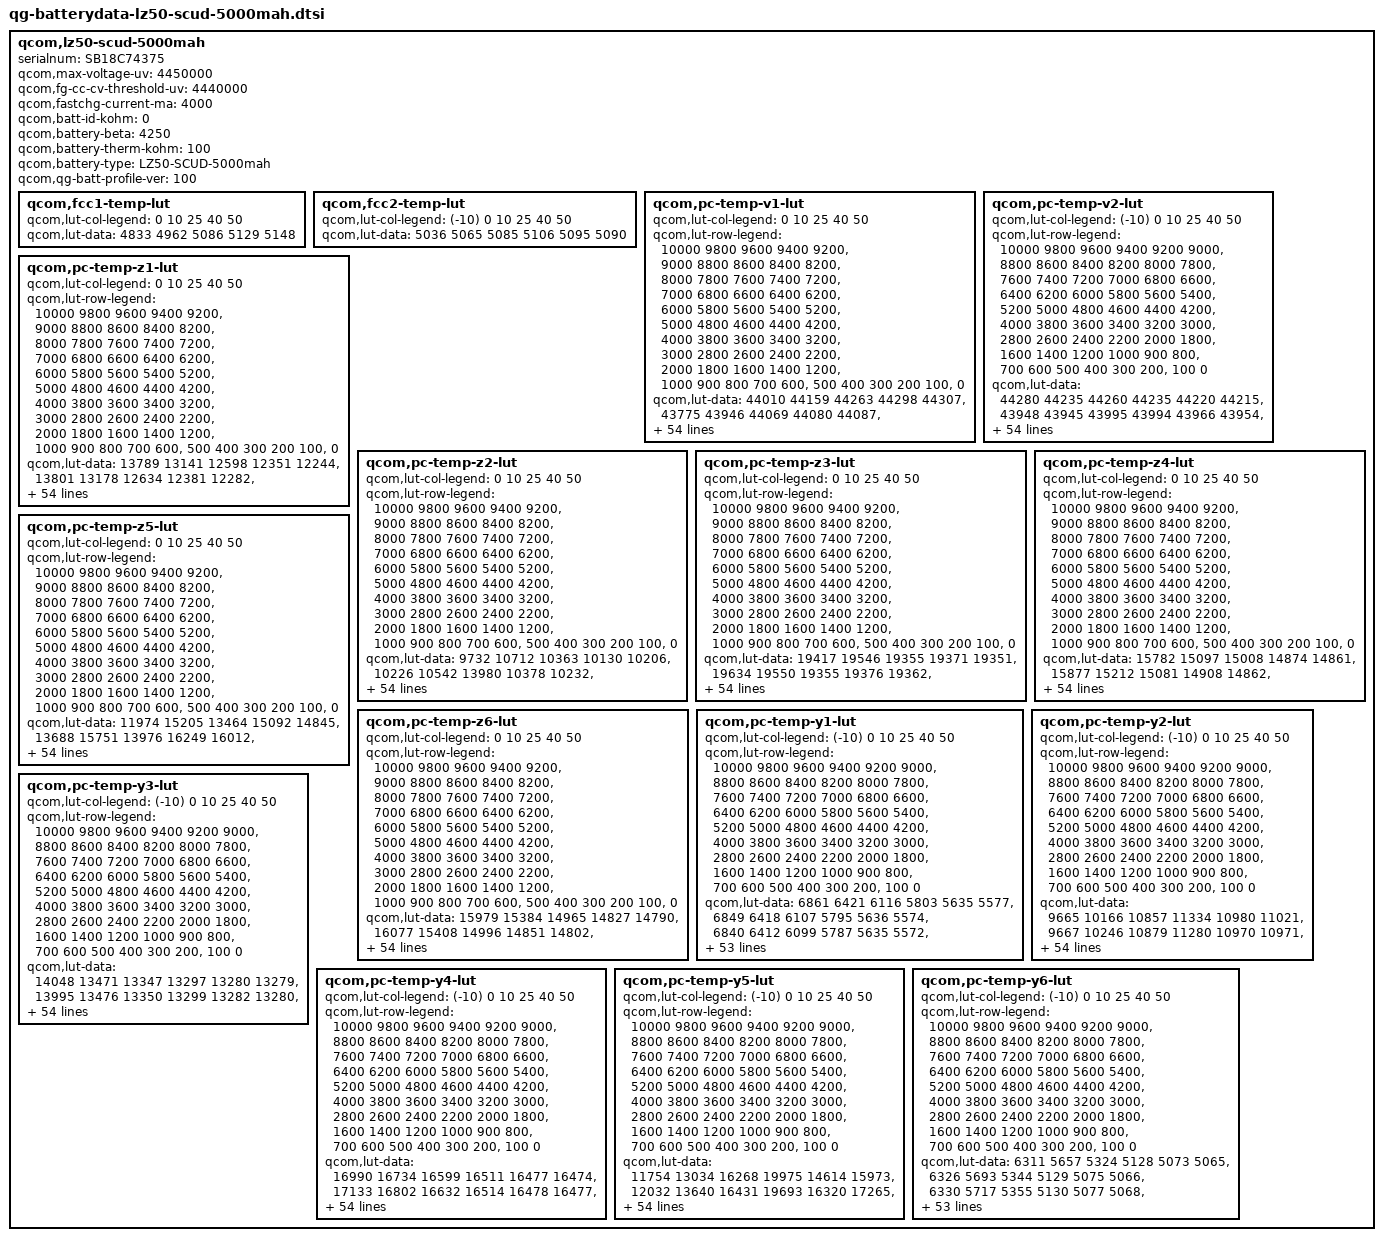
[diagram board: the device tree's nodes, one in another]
qcom,lz50-scud-5000mah {
    /* 4534034_lenovo_Nairobi_5000mAH_PM7250B_averaged_MasterSlave_Apr7th2020 */
    serialnum = "SB18C74375";
    qcom,max-voltage-uv = <4450000>;
    qcom,fg-cc-cv-threshold-uv = <4440000>;
    qcom,fastchg-current-ma = <4000>;
    qcom,batt-id-kohm = <0>;
    qcom,battery-beta = <4250>;
    qcom,battery-therm-kohm = <100>;
    qcom,battery-type = "LZ50-SCUD-5000mah";
    qcom,qg-batt-profile-ver = <100>;

	qcom,fcc1-temp-lut {
		qcom,lut-col-legend = <0 10 25 40 50>;
		qcom,lut-data = <4833 4962 5086 5129 5148>;
	};

	qcom,fcc2-temp-lut {
		qcom,lut-col-legend = <(-10) 0 10 25 40 50>;
		qcom,lut-data = <5036 5065 5085 5106 5095 5090>;
	};

	qcom,pc-temp-v1-lut {
		qcom,lut-col-legend = <0 10 25 40 50>;
		qcom,lut-row-legend = <10000 9800 9600 9400 9200>,
			<9000 8800 8600 8400 8200>,
			<8000 7800 7600 7400 7200>,
			<7000 6800 6600 6400 6200>,
			<6000 5800 5600 5400 5200>,
			<5000 4800 4600 4400 4200>,
			<4000 3800 3600 3400 3200>,
			<3000 2800 2600 2400 2200>,
			<2000 1800 1600 1400 1200>,
			<1000 900 800 700 600>,
			<500 400 300 200 100>,
			<0>;
		qcom,lut-data = <44010 44159 44263 44298 44307>,
			<43775 43946 44069 44080 44087>,
			<43539 43727 43872 43880 43887>,
			<43300 43501 43660 43678 43686>,
			<43059 43270 43435 43466 43477>,
			<42814 43032 43194 43239 43255>,
			<42572 42787 42950 43005 43023>,
			<42332 42542 42705 42766 42785>,
			<42096 42299 42459 42522 42539>,
			<41865 42057 42214 42278 42294>,
			<41639 41822 41972 42034 42051>,
			<41419 41590 41733 41793 41811>,
			<41203 41364 41499 41556 41573>,
			<40993 41149 41271 41322 41338>,
			<40779 40941 41050 41096 41111>,
			<40558 40732 40837 40876 40889>,
			<40343 40518 40627 40664 40675>,
			<40153 40312 40421 40460 40471>,
			<39981 40128 40223 40264 40276>,
			<39817 39957 40049 40082 40091>,
			<39659 39782 39879 39912 39922>,
			<39506 39605 39656 39709 39727>,
			<39357 39419 39349 39414 39443>,
			<39211 39196 39098 39140 39164>,
			<39066 38943 38952 38990 39008>,
			<38919 38767 38840 38882 38902>,
			<38774 38668 38741 38778 38796>,
			<38654 38594 38653 38674 38684>,
			<38557 38526 38571 38576 38575>,
			<38476 38466 38493 38484 38473>,
			<38419 38412 38421 38397 38378>,
			<38374 38360 38353 38318 38296>,
			<38334 38313 38290 38245 38226>,
			<38297 38268 38232 38177 38159>,
			<38262 38228 38181 38114 38090>,
			<38226 38188 38132 38055 38021>,
			<38191 38149 38082 37998 37955>,
			<38150 38107 38030 37944 37893>,
			<38087 38044 37964 37876 37817>,
			<38004 37950 37872 37776 37709>,
			<37905 37841 37763 37658 37584>,
			<37777 37717 37643 37540 37462>,
			<37631 37575 37506 37411 37333>,
			<37459 37408 37344 37254 37172>,
			<37339 37257 37195 37116 37041>,
			<37233 37161 37100 37027 36965>,
			<37193 37127 37069 36999 36935>,
			<37159 37111 37051 36977 36913>,
			<37123 37081 37028 36954 36887>,
			<37061 37022 36960 36879 36798>,
			<36834 36770 36692 36589 36478>,
			<36379 36312 36242 36134 36021>,
			<35785 35712 35651 35544 35427>,
			<34963 34881 34840 34738 34612>,
			<33626 33554 33574 33482 33333>,
			<30000 30000 30000 30000 30000>;
	};

	qcom,pc-temp-v2-lut {
		qcom,lut-col-legend = <(-10) 0 10 25 40 50>;
		qcom,lut-row-legend = <10000 9800 9600 9400 9200 9000>,
			<8800 8600 8400 8200 8000 7800>,
			<7600 7400 7200 7000 6800 6600>,
			<6400 6200 6000 5800 5600 5400>,
			<5200 5000 4800 4600 4400 4200>,
			<4000 3800 3600 3400 3200 3000>,
			<2800 2600 2400 2200 2000 1800>,
			<1600 1400 1200 1000 900 800>,
			<700 600 500 400 300 200>,
			<100 0>;
		qcom,lut-data = <44280 44235 44260 44235 44220 44215>,
			<43948 43945 43995 43994 43966 43954>,
			<43632 43672 43739 43759 43723 43706>,
			<43332 43418 43497 43531 43493 43475>,
			<43048 43184 43268 43312 43276 43259>,
			<42773 42946 43034 43085 43052 43038>,
			<42501 42694 42785 42845 42812 42800>,
			<42236 42437 42532 42599 42566 42556>,
			<41978 42183 42282 42353 42321 42311>,
			<41724 41929 42033 42106 42076 42065>,
			<41494 41677 41788 41862 41835 41822>,
			<41293 41414 41547 41621 41596 41584>,
			<41106 41168 41312 41385 41361 41350>,
			<40920 40986 41086 41153 41129 41120>,
			<40742 40846 40869 40926 40903 40895>,
			<40520 40661 40654 40706 40685 40677>,
			<40164 40356 40446 40493 40475 40467>,
			<39779 40027 40231 40286 40272 40263>,
			<39521 39777 39995 40094 40082 40076>,
			<39325 39562 39745 39906 39899 39895>,
			<39134 39349 39508 39692 39692 39692>,
			<38928 39132 39283 39435 39449 39455>,
			<38736 38924 39077 39194 39215 39223>,
			<38579 38728 38896 38994 39012 39019>,
			<38441 38543 38734 38817 38828 38832>,
			<38334 38392 38588 38669 38678 38679>,
			<38253 38265 38460 38542 38553 38552>,
			<38184 38163 38341 38430 38442 38440>,
			<38119 38090 38226 38328 38340 38336>,
			<38057 38031 38119 38233 38246 38242>,
			<37998 37975 38028 38145 38161 38157>,
			<37938 37923 37947 38062 38085 38081>,
			<37879 37872 37881 37985 38010 38005>,
			<37816 37819 37831 37916 37940 37930>,
			<37751 37766 37788 37849 37866 37851>,
			<37684 37709 37743 37779 37776 37753>,
			<37616 37646 37697 37709 37674 37636>,
			<37544 37577 37642 37634 37575 37526>,
			<37463 37498 37566 37555 37486 37432>,
			<37376 37410 37473 37472 37399 37341>,
			<37289 37312 37362 37383 37312 37254>,
			<37203 37203 37230 37285 37221 37165>,
			<37119 37093 37105 37158 37087 37030>,
			<37039 36984 36987 37025 36956 36898>,
			<36957 36878 36880 36915 36865 36811>,
			<36870 36758 36777 36862 36824 36774>,
			<36817 36699 36726 36845 36812 36762>,
			<36762 36644 36671 36821 36791 36741>,
			<36697 36590 36589 36775 36750 36695>,
			<36601 36499 36446 36661 36591 36524>,
			<36434 36319 36172 36327 36202 36132>,
			<36127 35903 35700 35800 35662 35594>,
			<35605 35271 35035 35109 34945 34881>,
			<34828 34330 34088 34137 33911 33873>,
			<33487 32806 32471 32663 32573 32513>,
			<31264 28190 27430 27573 28098 27439>;
	};

	qcom,pc-temp-z1-lut {
		qcom,lut-col-legend = <0 10 25 40 50>;
		qcom,lut-row-legend = <10000 9800 9600 9400 9200>,
			<9000 8800 8600 8400 8200>,
			<8000 7800 7600 7400 7200>,
			<7000 6800 6600 6400 6200>,
			<6000 5800 5600 5400 5200>,
			<5000 4800 4600 4400 4200>,
			<4000 3800 3600 3400 3200>,
			<3000 2800 2600 2400 2200>,
			<2000 1800 1600 1400 1200>,
			<1000 900 800 700 600>,
			<500 400 300 200 100>,
			<0>;
		qcom,lut-data = <13789 13141 12598 12351 12244>,
			<13801 13178 12634 12381 12282>,
			<13795 13197 12637 12383 12284>,
			<13789 13193 12638 12385 12283>,
			<13795 13183 12635 12384 12282>,
			<13817 13179 12627 12379 12280>,
			<13830 13183 12620 12372 12277>,
			<13814 13186 12615 12365 12274>,
			<13785 13182 12610 12358 12271>,
			<13776 13172 12602 12353 12269>,
			<13779 13162 12593 12349 12269>,
			<13782 13145 12589 12347 12270>,
			<13765 13130 12587 12348 12272>,
			<13723 13128 12586 12351 12275>,
			<13704 13130 12585 12351 12276>,
			<13706 13128 12583 12351 12276>,
			<13709 13111 12582 12350 12276>,
			<13708 13096 12583 12350 12276>,
			<13705 13099 12584 12349 12277>,
			<13700 13113 12585 12349 12277>,
			<13675 13120 12587 12351 12278>,
			<13640 13117 12588 12352 12279>,
			<13634 13114 12587 12352 12280>,
			<13653 13116 12587 12352 12280>,
			<13670 13120 12590 12353 12281>,
			<13676 13123 12596 12356 12282>,
			<13678 13129 12600 12358 12284>,
			<13679 13135 12604 12361 12287>,
			<13677 13136 12607 12365 12291>,
			<13675 13136 12611 12369 12295>,
			<13679 13137 12614 12373 12298>,
			<13688 13141 12617 12378 12303>,
			<13694 13145 12620 12385 12307>,
			<13693 13151 12623 12391 12312>,
			<13690 13159 12629 12396 12317>,
			<13690 13167 12635 12401 12323>,
			<13693 13175 12640 12406 12329>,
			<13698 13184 12644 12412 12333>,
			<13709 13194 12649 12418 12338>,
			<13729 13207 12658 12423 12342>,
			<13747 13216 12668 12428 12347>,
			<13781 13221 12675 12433 12352>,
			<13800 13226 12681 12439 12356>,
			<13802 13240 12688 12446 12360>,
			<13817 13262 12702 12454 12366>,
			<13844 13271 12708 12460 12370>,
			<13823 13263 12713 12459 12369>,
			<13825 13264 12707 12461 12371>,
			<13844 13255 12711 12466 12376>,
			<13840 13284 12712 12474 12383>,
			<13862 13273 12731 12481 12389>,
			<13863 13287 12738 12487 12399>,
			<13873 13313 12752 12506 12411>,
			<13891 13351 12778 12524 12431>,
			<13891 13351 12778 12524 12431>,
			<13891 13351 12778 12524 12431>;
	};

	qcom,pc-temp-z2-lut {
		qcom,lut-col-legend = <0 10 25 40 50>;
		qcom,lut-row-legend = <10000 9800 9600 9400 9200>,
			<9000 8800 8600 8400 8200>,
			<8000 7800 7600 7400 7200>,
			<7000 6800 6600 6400 6200>,
			<6000 5800 5600 5400 5200>,
			<5000 4800 4600 4400 4200>,
			<4000 3800 3600 3400 3200>,
			<3000 2800 2600 2400 2200>,
			<2000 1800 1600 1400 1200>,
			<1000 900 800 700 600>,
			<500 400 300 200 100>,
			<0>;
		qcom,lut-data = <9732 10712 10363 10130 10206>,
			<10226 10542 13980 10378 10232>,
			<10245 10432 13101 10446 10375>,
			<10250 10408 11720 10474 10406>,
			<10247 10393 11065 10479 10417>,
			<10242 10374 10636 10458 10413>,
			<10237 10344 10463 10425 10405>,
			<10231 10315 10422 10385 10391>,
			<10225 10290 10391 10337 10362>,
			<10223 10268 10365 10306 10330>,
			<10260 10254 10344 10282 10285>,
			<10296 10242 10326 10269 10254>,
			<10272 10236 10309 10265 10255>,
			<10202 10237 10299 10264 10261>,
			<10157 10240 10306 10268 10266>,
			<10136 10245 10325 10278 10278>,
			<10120 10257 10340 10292 10292>,
			<10135 10273 10355 10315 10303>,
			<10213 10289 10369 10339 10308>,
			<10266 10307 10383 10342 10286>,
			<10231 10322 10397 10335 10212>,
			<10170 10336 10435 10343 10175>,
			<10158 10348 10542 10494 10364>,
			<10171 10362 10606 10644 10595>,
			<10186 10377 10532 10543 10540>,
			<10200 10383 10419 10280 10301>,
			<10212 10376 10403 10206 10215>,
			<10222 10367 10418 10290 10374>,
			<10229 10365 10433 10379 10533>,
			<10235 10365 10446 10431 10588>,
			<10238 10366 10460 10486 10650>,
			<10239 10370 10475 10514 10613>,
			<10242 10375 10494 10513 10491>,
			<10247 10380 10504 10494 10371>,
			<10255 10386 10501 10448 10278>,
			<10262 10392 10498 10398 10203>,
			<10272 10399 10503 10391 10180>,
			<10282 10408 10514 10405 10186>,
			<10292 10420 10529 10425 10213>,
			<10304 10438 10564 10484 10320>,
			<10316 10448 10594 10543 10444>,
			<10328 10448 10599 10556 10488>,
			<10348 10449 10601 10561 10511>,
			<10394 10464 10597 10549 10535>,
			<9986 10574 10619 10490 10494>,
			<9784 10652 10650 10378 10301>,
			<9774 10634 10631 10377 10281>,
			<9851 10665 10609 10372 10280>,
			<9846 10728 10596 10395 10317>,
			<9799 10607 10638 10477 10377>,
			<9757 10717 10700 10413 10305>,
			<9700 10552 10631 10232 10108>,
			<9531 10372 10551 10172 10027>,
			<9405 10176 10451 10110 9984>,
			<9405 10176 10451 10110 9984>,
			<9405 10176 10451 10110 9984>;
	};

	qcom,pc-temp-z3-lut {
		qcom,lut-col-legend = <0 10 25 40 50>;
		qcom,lut-row-legend = <10000 9800 9600 9400 9200>,
			<9000 8800 8600 8400 8200>,
			<8000 7800 7600 7400 7200>,
			<7000 6800 6600 6400 6200>,
			<6000 5800 5600 5400 5200>,
			<5000 4800 4600 4400 4200>,
			<4000 3800 3600 3400 3200>,
			<3000 2800 2600 2400 2200>,
			<2000 1800 1600 1400 1200>,
			<1000 900 800 700 600>,
			<500 400 300 200 100>,
			<0>;
		qcom,lut-data = <19417 19546 19355 19371 19351>,
			<19634 19550 19355 19376 19362>,
			<19699 19556 19382 19397 19384>,
			<19739 19567 19418 19408 19397>,
			<19755 19580 19442 19417 19407>,
			<19764 19588 19461 19427 19415>,
			<19767 19593 19469 19433 19421>,
			<19762 19596 19470 19434 19427>,
			<19752 19596 19471 19434 19433>,
			<19750 19595 19470 19434 19435>,
			<19762 19593 19468 19433 19434>,
			<19774 19591 19466 19432 19432>,
			<19768 19588 19463 19430 19429>,
			<19748 19582 19460 19426 19425>,
			<19739 19574 19455 19422 19421>,
			<19750 19568 19449 19418 19417>,
			<19763 19564 19445 19414 19412>,
			<19769 19559 19442 19410 19407>,
			<19773 19554 19439 19406 19400>,
			<19774 19547 19435 19400 19393>,
			<19762 19545 19430 19392 19384>,
			<19743 19550 19432 19390 19379>,
			<19737 19557 19450 19400 19386>,
			<19736 19566 19461 19410 19393>,
			<19735 19577 19451 19400 19386>,
			<19738 19581 19434 19375 19361>,
			<19744 19577 19427 19368 19352>,
			<19746 19572 19423 19373 19376>,
			<19743 19567 19422 19379 19401>,
			<19738 19562 19424 19390 19413>,
			<19732 19559 19428 19403 19428>,
			<19722 19557 19433 19409 19428>,
			<19712 19555 19441 19415 19419>,
			<19704 19553 19444 19417 19409>,
			<19696 19552 19443 19413 19400>,
			<19689 19550 19442 19406 19390>,
			<19681 19546 19438 19399 19382>,
			<19674 19541 19433 19388 19373>,
			<19667 19537 19429 19384 19369>,
			<19660 19534 19427 19384 19369>,
			<19652 19530 19424 19384 19369>,
			<19641 19525 19421 19384 19371>,
			<19629 19518 19417 19384 19377>,
			<19616 19510 19413 19384 19383>,
			<19345 19483 19405 19378 19380>,
			<19267 19451 19390 19363 19361>,
			<19267 19443 19389 19357 19353>,
			<19266 19337 19382 19355 19348>,
			<19266 19321 19377 19345 19336>,
			<19266 19293 19369 19338 19336>,
			<19267 19320 19368 19358 19364>,
			<19268 19323 19380 19379 19375>,
			<19273 19323 19386 19382 19375>,
			<19286 19335 19385 19380 19376>,
			<19286 19335 19385 19380 19376>,
			<19286 19335 19385 19380 19376>;
	};

	qcom,pc-temp-z4-lut {
		qcom,lut-col-legend = <0 10 25 40 50>;
		qcom,lut-row-legend = <10000 9800 9600 9400 9200>,
			<9000 8800 8600 8400 8200>,
			<8000 7800 7600 7400 7200>,
			<7000 6800 6600 6400 6200>,
			<6000 5800 5600 5400 5200>,
			<5000 4800 4600 4400 4200>,
			<4000 3800 3600 3400 3200>,
			<3000 2800 2600 2400 2200>,
			<2000 1800 1600 1400 1200>,
			<1000 900 800 700 600>,
			<500 400 300 200 100>,
			<0>;
		qcom,lut-data = <15782 15097 15008 14874 14861>,
			<15877 15212 15081 14908 14862>,
			<15791 15270 15047 14928 14896>,
			<15638 15233 14992 14904 14881>,
			<15513 15129 14952 14879 14863>,
			<15396 15047 14917 14857 14846>,
			<15296 14987 14885 14835 14828>,
			<15222 14937 14856 14817 14810>,
			<15161 14897 14829 14801 14793>,
			<15098 14864 14807 14785 14778>,
			<15022 14837 14788 14769 14764>,
			<14962 14814 14772 14755 14751>,
			<14942 14795 14756 14741 14739>,
			<14927 14779 14743 14728 14727>,
			<14913 14766 14733 14720 14721>,
			<14889 14756 14724 14715 14717>,
			<14862 14748 14719 14711 14714>,
			<14835 14742 14715 14707 14711>,
			<14800 14736 14712 14703 14708>,
			<14777 14731 14708 14701 14707>,
			<14777 14728 14703 14700 14706>,
			<14783 14728 14713 14702 14707>,
			<14781 14730 14777 14761 14760>,
			<14775 14751 14829 14826 14829>,
			<14770 14811 14844 14843 14845>,
			<14776 14838 14853 14852 14853>,
			<14790 14833 14851 14853 14852>,
			<14799 14823 14839 14836 14816>,
			<14804 14813 14824 14813 14773>,
			<14807 14800 14809 14789 14750>,
			<14806 14788 14792 14764 14724>,
			<14797 14776 14776 14744 14713>,
			<14789 14765 14759 14725 14708>,
			<14781 14755 14746 14715 14705>,
			<14773 14746 14735 14711 14704>,
			<14764 14739 14727 14709 14703>,
			<14756 14731 14724 14707 14703>,
			<14748 14725 14721 14705 14701>,
			<14740 14723 14721 14705 14701>,
			<14733 14722 14724 14713 14712>,
			<14729 14721 14727 14722 14725>,
			<14728 14717 14725 14720 14721>,
			<14725 14711 14719 14713 14709>,
			<14712 14703 14714 14711 14708>,
			<14913 14683 14697 14702 14701>,
			<14973 14677 14673 14680 14676>,
			<14970 14680 14666 14677 14675>,
			<14966 14791 14658 14664 14663>,
			<14961 14803 14647 14651 14647>,
			<14952 14827 14650 14649 14639>,
			<14947 14802 14676 14670 14667>,
			<14968 14813 14675 14670 14677>,
			<14982 14821 14673 14673 14685>,
			<15005 14824 14679 14680 14690>,
			<15005 14824 14679 14680 14690>,
			<15005 14824 14679 14680 14690>;
	};

	qcom,pc-temp-z5-lut {
		qcom,lut-col-legend = <0 10 25 40 50>;
		qcom,lut-row-legend = <10000 9800 9600 9400 9200>,
			<9000 8800 8600 8400 8200>,
			<8000 7800 7600 7400 7200>,
			<7000 6800 6600 6400 6200>,
			<6000 5800 5600 5400 5200>,
			<5000 4800 4600 4400 4200>,
			<4000 3800 3600 3400 3200>,
			<3000 2800 2600 2400 2200>,
			<2000 1800 1600 1400 1200>,
			<1000 900 800 700 600>,
			<500 400 300 200 100>,
			<0>;
		qcom,lut-data = <11974 15205 13464 15092 14845>,
			<13688 15751 13976 16249 16012>,
			<14402 16224 14702 17400 17449>,
			<14925 16641 15679 18199 18537>,
			<15349 17144 16747 18948 19478>,
			<15696 17677 18019 19755 20247>,
			<15956 18216 18888 20364 20987>,
			<16116 18787 19331 20627 21973>,
			<16246 19389 19717 20808 23170>,
			<16528 20026 20189 21106 24093>,
			<17425 20752 20711 21705 24662>,
			<18255 21695 21295 22467 25248>,
			<18361 22481 22018 23422 26255>,
			<18285 22878 22810 24519 27551>,
			<18395 23224 23584 25414 28559>,
			<19815 23702 24383 26162 29384>,
			<21798 25126 25261 26926 29963>,
			<23300 26494 26316 27951 30330>,
			<25245 26823 27288 28798 30554>,
			<26465 26927 27874 28757 30250>,
			<26622 27501 28424 28124 28950>,
			<26826 31754 31385 28103 28245>,
			<27852 37854 43424 31894 29641>,
			<31211 43505 51051 35658 31374>,
			<35513 49527 43196 31873 28807>,
			<40435 51660 30453 22124 20358>,
			<45838 46985 25859 18638 17090>,
			<47778 40544 23735 18334 19763>,
			<47501 37372 23013 18433 22714>,
			<46718 35136 23220 19630 25437>,
			<45147 34365 23699 21964 29889>,
			<41974 34564 24874 24315 30910>,
			<39485 34995 27687 27590 30207>,
			<38031 35866 30319 29977 29534>,
			<36920 37685 32861 31261 29194>,
			<36225 38904 34841 32130 28930>,
			<35448 39289 35503 31850 28627>,
			<35085 39560 35880 30459 27704>,
			<35473 39935 35911 29815 27227>,
			<36055 40458 35541 30327 27445>,
			<35990 40687 34895 30887 27712>,
			<33784 38563 32990 29625 27655>,
			<32646 36207 30419 26974 27541>,
			<33660 35377 29860 27468 30282>,
			<16761 34914 30848 27413 31212>,
			<11555 27913 29922 24388 24387>,
			<11522 25371 30195 22164 21207>,
			<11461 13182 27473 23308 21696>,
			<11450 12667 27987 22654 22063>,
			<11480 12083 25597 21225 23495>,
			<11525 12828 21435 22381 26294>,
			<11456 12701 21282 23312 22992>,
			<11363 12524 21263 22113 20020>,
			<11310 12584 19673 19265 17707>,
			<11310 12584 19673 19265 17707>,
			<11310 12584 19673 19265 17707>;
	};

	qcom,pc-temp-z6-lut {
		qcom,lut-col-legend = <0 10 25 40 50>;
		qcom,lut-row-legend = <10000 9800 9600 9400 9200>,
			<9000 8800 8600 8400 8200>,
			<8000 7800 7600 7400 7200>,
			<7000 6800 6600 6400 6200>,
			<6000 5800 5600 5400 5200>,
			<5000 4800 4600 4400 4200>,
			<4000 3800 3600 3400 3200>,
			<3000 2800 2600 2400 2200>,
			<2000 1800 1600 1400 1200>,
			<1000 900 800 700 600>,
			<500 400 300 200 100>,
			<0>;
		qcom,lut-data = <15979 15384 14965 14827 14790>,
			<16077 15408 14996 14851 14802>,
			<16029 15413 14989 14865 14826>,
			<15945 15390 14980 14861 14826>,
			<15870 15330 14970 14857 14826>,
			<15796 15281 14958 14851 14824>,
			<15728 15242 14945 14844 14819>,
			<15672 15209 14930 14836 14815>,
			<15623 15181 14915 14828 14810>,
			<15581 15156 14902 14820 14805>,
			<15544 15135 14890 14813 14799>,
			<15512 15117 14879 14806 14793>,
			<15484 15101 14870 14799 14786>,
			<15460 15086 14862 14792 14780>,
			<15440 15072 14854 14786 14775>,
			<15424 15060 14846 14781 14770>,
			<15411 15050 14841 14777 14766>,
			<15396 15043 14838 14773 14762>,
			<15380 15036 14835 14769 14757>,
			<15367 15031 14830 14764 14752>,
			<15355 15030 14827 14760 14747>,
			<15345 15033 14832 14759 14745>,
			<15339 15039 14872 14792 14772>,
			<15335 15055 14897 14825 14806>,
			<15333 15087 14896 14824 14806>,
			<15338 15102 14894 14818 14799>,
			<15350 15099 14891 14812 14793>,
			<15356 15093 14885 14808 14790>,
			<15357 15088 14880 14804 14787>,
			<15358 15082 14875 14800 14785>,
			<15357 15077 14871 14797 14782>,
			<15350 15072 14868 14793 14778>,
			<15343 15068 14866 14790 14772>,
			<15338 15066 14864 14786 14766>,
			<15334 15064 14860 14783 14761>,
			<15330 15062 14857 14780 14757>,
			<15327 15060 14855 14776 14752>,
			<15325 15058 14853 14770 14747>,
			<15326 15058 14852 14768 14745>,
			<15328 15061 14855 14772 14750>,
			<15331 15064 14857 14777 14756>,
			<15335 15065 14856 14776 14756>,
			<15339 15065 14854 14774 14755>,
			<15343 15066 14853 14774 14757>,
			<15318 15058 14846 14769 14754>,
			<15309 15045 14832 14753 14733>,
			<15308 15042 14829 14749 14729>,
			<15306 15037 14822 14742 14721>,
			<15307 15037 14816 14731 14708>,
			<15311 15038 14817 14729 14706>,
			<15318 15048 14830 14749 14733>,
			<15337 15062 14841 14763 14747>,
			<15359 15077 14849 14770 14754>,
			<15397 15102 14859 14778 14762>,
			<15397 15102 14859 14778 14762>,
			<15397 15102 14859 14778 14762>;
	};

	qcom,pc-temp-y1-lut {
		qcom,lut-col-legend = <(-10) 0 10 25 40 50>;
		qcom,lut-row-legend = <10000 9800 9600 9400 9200 9000>,
			<8800 8600 8400 8200 8000 7800>,
			<7600 7400 7200 7000 6800 6600>,
			<6400 6200 6000 5800 5600 5400>,
			<5200 5000 4800 4600 4400 4200>,
			<4000 3800 3600 3400 3200 3000>,
			<2800 2600 2400 2200 2000 1800>,
			<1600 1400 1200 1000 900 800>,
			<700 600 500 400 300 200>,
			<100 0>;
		qcom,lut-data = <6861 6421 6116 5803 5635 5577>,
			<6849 6418 6107 5795 5636 5574>,
			<6840 6412 6099 5787 5635 5572>,
			<6833 6406 6092 5780 5633 5569>,
			<6828 6401 6088 5774 5631 5567>,
			<6827 6399 6087 5769 5628 5564>,
			<6830 6399 6090 5766 5624 5562>,
			<6834 6400 6093 5764 5619 5560>,
			<6833 6401 6092 5761 5615 5558>,
			<6823 6402 6086 5758 5612 5556>,
			<6817 6404 6083 5757 5610 5554>,
			<6822 6402 6086 5756 5609 5552>,
			<6831 6399 6091 5756 5608 5551>,
			<6841 6400 6090 5754 5606 5550>,
			<6853 6405 6086 5751 5604 5550>,
			<6861 6409 6084 5750 5602 5549>,
			<6867 6417 6084 5750 5602 5549>,
			<6872 6423 6085 5750 5601 5548>,
			<6867 6423 6087 5751 5601 5549>,
			<6847 6420 6090 5751 5601 5549>,
			<6838 6419 6091 5751 5602 5549>,
			<6842 6418 6088 5752 5603 5550>,
			<6848 6417 6086 5753 5604 5550>,
			<6848 6419 6087 5755 5606 5552>,
			<6845 6425 6091 5758 5608 5554>,
			<6844 6426 6092 5761 5610 5555>,
			<6850 6426 6092 5764 5612 5557>,
			<6859 6424 6093 5767 5614 5559>,
			<6857 6420 6095 5770 5617 5562>,
			<6852 6414 6097 5773 5621 5564>,
			<6847 6411 6097 5776 5624 5567>,
			<6837 6410 6095 5780 5628 5571>,
			<6825 6410 6093 5782 5631 5574>,
			<6818 6407 6097 5785 5635 5576>,
			<6814 6404 6103 5786 5638 5579>,
			<6812 6402 6102 5787 5641 5581>,
			<6820 6401 6096 5788 5644 5584>,
			<6828 6400 6094 5789 5645 5586>,
			<6828 6400 6095 5795 5646 5587>,
			<6824 6400 6098 5799 5646 5589>,
			<6818 6401 6101 5799 5648 5590>,
			<6803 6401 6106 5799 5651 5592>,
			<6798 6401 6099 5801 5654 5595>,
			<6816 6404 6096 5807 5659 5599>,
			<6838 6426 6106 5810 5664 5603>,
			<6863 6427 6107 5818 5667 5604>,
			<6859 6427 6112 5823 5666 5604>,
			<6852 6424 6120 5818 5666 5604>,
			<6877 6450 6127 5820 5666 5604>,
			<6874 6441 6123 5819 5666 5606>,
			<6872 6459 6127 5821 5672 5611>,
			<6922 6477 6138 5838 5682 5618>,
			<7046 6503 6162 5857 5694 5628>,
			<7190 6622 6224 5883 5710 5641>,
			<7190 6622 6224 5883 5710 5641>,
			<7190 6622 6224 5883 5710 5641>;
	};

	qcom,pc-temp-y2-lut {
		qcom,lut-col-legend = <(-10) 0 10 25 40 50>;
		qcom,lut-row-legend = <10000 9800 9600 9400 9200 9000>,
			<8800 8600 8400 8200 8000 7800>,
			<7600 7400 7200 7000 6800 6600>,
			<6400 6200 6000 5800 5600 5400>,
			<5200 5000 4800 4600 4400 4200>,
			<4000 3800 3600 3400 3200 3000>,
			<2800 2600 2400 2200 2000 1800>,
			<1600 1400 1200 1000 900 800>,
			<700 600 500 400 300 200>,
			<100 0>;
		qcom,lut-data = <9665 10166 10857 11334 10980 11021>,
			<9667 10246 10879 11280 10970 10971>,
			<9670 10340 10895 11228 10956 10921>,
			<9672 10433 10905 11180 10938 10874>,
			<9675 10510 10911 11138 10919 10834>,
			<9676 10556 10912 11104 10899 10805>,
			<9677 10581 10902 11078 10870 10786>,
			<9677 10596 10888 11056 10842 10770>,
			<9677 10596 10888 11037 10835 10751>,
			<9675 10586 10896 11021 10833 10729>,
			<9674 10583 10905 11014 10833 10717>,
			<9674 10701 10913 11013 10847 10713>,
			<9674 10840 10926 11012 10859 10711>,
			<9674 10852 10955 11015 10853 10708>,
			<9674 10846 11011 11029 10845 10698>,
			<9674 10844 11065 11050 10845 10697>,
			<9673 10875 11128 11097 10880 10729>,
			<9670 10915 11169 11159 10934 10781>,
			<9669 10931 11170 11251 11003 10842>,
			<9668 10942 11166 11355 11089 10918>,
			<9667 10927 11164 11372 11146 10984>,
			<9667 10636 11166 11334 11189 11058>,
			<9666 10344 11169 11302 11210 11099>,
			<9666 10168 11176 11293 11174 11063>,
			<9665 9827 11188 11286 11110 11000>,
			<9665 9711 11196 11291 11100 10992>,
			<9665 9702 11202 11329 11127 11027>,
			<9664 9696 11205 11372 11163 11068>,
			<9664 9690 11192 11414 11224 11099>,
			<9663 9686 11168 11451 11294 11132>,
			<9663 9681 11154 11469 11322 11183>,
			<9663 9678 11147 11481 11339 11275>,
			<9663 9675 11138 11483 11357 11340>,
			<9662 9672 11117 11464 11390 11403>,
			<9662 9670 11087 11444 11421 11457>,
			<9662 9668 11051 11443 11399 11406>,
			<9662 9666 11005 11447 11314 11235>,
			<9662 9664 10935 11444 11261 11141>,
			<9662 9663 10682 11411 11241 11114>,
			<9662 9662 10363 11372 11230 11098>,
			<9661 9662 10100 11350 11242 11113>,
			<9661 9661 9765 11330 11269 11152>,
			<9661 9660 9711 11306 11216 11084>,
			<9661 9660 9693 11248 11104 10950>,
			<9660 9659 9687 11219 11002 10846>,
			<9660 9659 9681 11174 10986 10848>,
			<9659 9659 9677 11167 11017 10864>,
			<9659 9659 9675 11171 11024 10893>,
			<9658 9658 9673 11176 11085 10904>,
			<9657 9658 9670 11169 11021 10850>,
			<9656 9657 9666 11088 10949 10751>,
			<9653 9656 9662 10989 10850 10650>,
			<9651 9654 9658 10867 10757 10581>,
			<9650 9652 9655 10732 10625 10469>,
			<9650 9652 9655 10732 10625 10469>,
			<9650 9652 9655 10732 10625 10469>;
	};

	qcom,pc-temp-y3-lut {
		qcom,lut-col-legend = <(-10) 0 10 25 40 50>;
		qcom,lut-row-legend = <10000 9800 9600 9400 9200 9000>,
			<8800 8600 8400 8200 8000 7800>,
			<7600 7400 7200 7000 6800 6600>,
			<6400 6200 6000 5800 5600 5400>,
			<5200 5000 4800 4600 4400 4200>,
			<4000 3800 3600 3400 3200 3000>,
			<2800 2600 2400 2200 2000 1800>,
			<1600 1400 1200 1000 900 800>,
			<700 600 500 400 300 200>,
			<100 0>;
		qcom,lut-data = <14048 13471 13347 13297 13280 13279>,
			<13995 13476 13350 13299 13282 13280>,
			<13941 13481 13354 13300 13284 13283>,
			<13891 13484 13358 13302 13286 13285>,
			<13848 13486 13361 13303 13288 13286>,
			<13818 13487 13363 13304 13289 13288>,
			<13800 13486 13364 13305 13289 13288>,
			<13786 13483 13365 13306 13289 13289>,
			<13763 13479 13366 13306 13289 13289>,
			<13729 13472 13367 13307 13291 13289>,
			<13701 13464 13368 13307 13293 13289>,
			<13679 13457 13366 13308 13294 13291>,
			<13664 13450 13364 13308 13295 13292>,
			<13667 13441 13362 13308 13295 13293>,
			<13687 13431 13358 13308 13296 13293>,
			<13697 13423 13357 13308 13297 13294>,
			<13660 13419 13356 13308 13299 13294>,
			<13612 13415 13355 13308 13300 13294>,
			<13607 13408 13352 13308 13300 13295>,
			<13611 13398 13346 13309 13300 13297>,
			<13616 13391 13341 13308 13299 13297>,
			<13621 13387 13336 13305 13295 13294>,
			<13628 13384 13332 13301 13292 13290>,
			<13634 13380 13330 13297 13288 13287>,
			<13640 13376 13327 13295 13285 13284>,
			<13649 13371 13325 13293 13284 13283>,
			<13673 13363 13324 13292 13284 13282>,
			<13705 13357 13322 13292 13284 13282>,
			<13737 13364 13321 13293 13283 13282>,
			<13772 13382 13319 13293 13283 13282>,
			<13810 13400 13318 13293 13283 13282>,
			<13849 13420 13317 13292 13283 13282>,
			<13890 13445 13317 13292 13284 13283>,
			<13932 13477 13318 13292 13284 13283>,
			<13975 13516 13321 13292 13285 13284>,
			<14020 13560 13324 13292 13285 13284>,
			<14067 13612 13327 13293 13284 13282>,
			<14114 13671 13330 13293 13283 13281>,
			<14157 13740 13334 13293 13284 13282>,
			<14197 13818 13340 13293 13285 13283>,
			<14236 13896 13346 13294 13286 13285>,
			<14273 13975 13355 13295 13288 13287>,
			<14315 14058 13373 13296 13286 13284>,
			<14365 14143 13399 13296 13284 13283>,
			<14429 14210 13414 13295 13285 13285>,
			<14453 14246 13452 13300 13293 13293>,
			<14528 14316 13489 13305 13297 13295>,
			<14626 14391 13532 13309 13299 13297>,
			<14762 14472 13580 13313 13301 13297>,
			<14979 14569 13642 13315 13297 13293>,
			<15404 14734 13733 13312 13294 13291>,
			<16914 15091 13927 13314 13296 13294>,
			<21577 16528 14380 13324 13302 13299>,
			<36002 23150 15458 13344 13314 13313>,
			<36002 23150 15458 13344 13314 13313>,
			<36002 23150 15458 13344 13314 13313>;
	};

	qcom,pc-temp-y4-lut {
		qcom,lut-col-legend = <(-10) 0 10 25 40 50>;
		qcom,lut-row-legend = <10000 9800 9600 9400 9200 9000>,
			<8800 8600 8400 8200 8000 7800>,
			<7600 7400 7200 7000 6800 6600>,
			<6400 6200 6000 5800 5600 5400>,
			<5200 5000 4800 4600 4400 4200>,
			<4000 3800 3600 3400 3200 3000>,
			<2800 2600 2400 2200 2000 1800>,
			<1600 1400 1200 1000 900 800>,
			<700 600 500 400 300 200>,
			<100 0>;
		qcom,lut-data = <16990 16734 16599 16511 16477 16474>,
			<17133 16802 16632 16514 16478 16477>,
			<17279 16900 16674 16518 16480 16480>,
			<17407 17001 16717 16520 16481 16483>,
			<17498 17080 16749 16521 16483 16484>,
			<17531 17108 16760 16522 16484 16485>,
			<17500 17098 16755 16521 16485 16484>,
			<17455 17084 16748 16519 16486 16483>,
			<17447 17081 16743 16520 16487 16483>,
			<17459 17080 16739 16522 16488 16485>,
			<17467 17079 16738 16524 16490 16487>,
			<17483 17076 16743 16529 16493 16488>,
			<17504 17073 16754 16535 16497 16491>,
			<17495 17106 16773 16544 16501 16494>,
			<17438 17211 16804 16555 16507 16498>,
			<17359 17252 16824 16569 16514 16504>,
			<17227 17124 16836 16588 16522 16509>,
			<17083 16967 16842 16609 16532 16517>,
			<17011 16914 16822 16637 16553 16532>,
			<16968 16885 16765 16666 16581 16552>,
			<16922 16852 16714 16664 16586 16556>,
			<16856 16811 16670 16609 16565 16545>,
			<16798 16770 16634 16554 16538 16530>,
			<16769 16730 16609 16523 16511 16509>,
			<16749 16693 16590 16500 16487 16486>,
			<16743 16671 16578 16497 16482 16482>,
			<16743 16656 16571 16498 16484 16482>,
			<16744 16647 16563 16500 16486 16483>,
			<16745 16646 16548 16504 16492 16488>,
			<16748 16649 16532 16511 16500 16496>,
			<16751 16653 16522 16517 16510 16504>,
			<16753 16661 16515 16523 16522 16515>,
			<16756 16670 16512 16526 16529 16524>,
			<16761 16677 16520 16528 16534 16531>,
			<16768 16683 16536 16529 16536 16536>,
			<16771 16692 16554 16525 16529 16530>,
			<16772 16703 16576 16514 16506 16507>,
			<16772 16711 16596 16507 16494 16496>,
			<16773 16714 16612 16504 16492 16496>,
			<16773 16716 16626 16503 16491 16497>,
			<16774 16718 16640 16509 16497 16504>,
			<16777 16720 16653 16520 16508 16518>,
			<16781 16726 16664 16516 16493 16499>,
			<16790 16739 16679 16511 16475 16471>,
			<16805 16745 16686 16497 16469 16466>,
			<16786 16739 16715 16519 16501 16511>,
			<16800 16766 16756 16542 16536 16552>,
			<16819 16804 16817 16576 16576 16593>,
			<16844 16843 16887 16618 16614 16623>,
			<16868 16883 16958 16649 16582 16581>,
			<16879 16898 16987 16593 16508 16510>,
			<17024 16871 17007 16578 16506 16506>,
			<17824 16992 17079 16606 16512 16505>,
			<24905 20046 17302 16664 16542 16529>,
			<24905 20046 17302 16664 16542 16529>,
			<24905 20046 17302 16664 16542 16529>;
	};

	qcom,pc-temp-y5-lut {
		qcom,lut-col-legend = <(-10) 0 10 25 40 50>;
		qcom,lut-row-legend = <10000 9800 9600 9400 9200 9000>,
			<8800 8600 8400 8200 8000 7800>,
			<7600 7400 7200 7000 6800 6600>,
			<6400 6200 6000 5800 5600 5400>,
			<5200 5000 4800 4600 4400 4200>,
			<4000 3800 3600 3400 3200 3000>,
			<2800 2600 2400 2200 2000 1800>,
			<1600 1400 1200 1000 900 800>,
			<700 600 500 400 300 200>,
			<100 0>;
		qcom,lut-data = <11754 13034 16268 19975 14614 15973>,
			<12032 13640 16431 19693 16320 17265>,
			<12306 14228 16659 19407 17388 18229>,
			<12576 14781 16906 19115 17941 18885>,
			<12842 15279 17125 18820 18099 19255>,
			<13103 15705 17271 18522 17978 19359>,
			<13422 16139 17396 18230 17188 19088>,
			<13685 16463 17493 17923 16272 18617>,
			<13694 16454 17490 17561 16145 18114>,
			<13568 16232 17426 17142 16328 17356>,
			<13499 15972 17322 16727 16418 16876>,
			<13774 15576 16970 16332 16369 16876>,
			<14422 15230 16489 15925 16247 16940>,
			<16052 15678 16052 15426 15945 16665>,
			<19840 17366 15607 14884 15471 16140>,
			<21654 18594 15565 14620 15283 15666>,
			<18624 19196 17201 14492 15312 15196>,
			<14843 19651 19135 14452 15343 14898>,
			<14613 20026 19966 15042 15267 14891>,
			<15364 20339 20531 16530 15141 14927>,
			<15721 20519 20956 18213 15406 15219>,
			<15408 20000 21334 20565 17849 17295>,
			<14831 19236 21603 21886 19714 18925>,
			<14032 18088 21738 21322 19496 18869>,
			<12900 15944 21831 20294 18951 18649>,
			<12454 14529 21938 19719 18419 18276>,
			<12452 13303 22239 19303 17807 17254>,
			<12452 12512 22552 19141 17385 16448>,
			<12462 12484 22819 19641 16987 16121>,
			<12520 12610 23033 20298 16620 15914>,
			<12602 12711 22719 20426 16708 15924>,
			<12744 12796 21029 20457 17019 16159>,
			<12885 12911 20012 20543 17483 16539>,
			<12932 13172 20012 21488 18616 17607>,
			<12932 13530 20036 22653 19899 18896>,
			<12980 13737 20108 23142 20514 19463>,
			<13158 13857 20289 23538 20931 19804>,
			<13307 13972 20363 23568 21048 20014>,
			<13242 14144 19592 22381 20884 20145>,
			<13033 14297 18332 21054 20701 20246>,
			<12872 14284 16795 20345 20838 20471>,
			<12708 14102 14717 19782 21123 20873>,
			<12674 13921 14334 19725 20157 20138>,
			<12729 13778 14119 19052 18553 19318>,
			<12771 13839 13923 18937 17817 18374>,
			<12938 13611 14319 18306 17189 16942>,
			<12885 13695 14892 18471 17069 16068>,
			<13033 13856 15350 18107 16494 15480>,
			<13271 14671 15700 17940 16560 15187>,
			<13463 15172 16024 18359 16199 14974>,
			<13499 15416 15970 18719 17169 15655>,
			<12278 13830 14897 18825 17049 15561>,
			<10306 12257 13284 18347 17519 15826>,
			<9189 9849 11761 19201 21929 22686>,
			<9189 9849 11761 19201 21929 22686>,
			<9189 9849 11761 19201 21929 22686>;
	};

	qcom,pc-temp-y6-lut {
		qcom,lut-col-legend = <(-10) 0 10 25 40 50>;
		qcom,lut-row-legend = <10000 9800 9600 9400 9200 9000>,
			<8800 8600 8400 8200 8000 7800>,
			<7600 7400 7200 7000 6800 6600>,
			<6400 6200 6000 5800 5600 5400>,
			<5200 5000 4800 4600 4400 4200>,
			<4000 3800 3600 3400 3200 3000>,
			<2800 2600 2400 2200 2000 1800>,
			<1600 1400 1200 1000 900 800>,
			<700 600 500 400 300 200>,
			<100 0>;
		qcom,lut-data = <6311 5657 5324 5128 5073 5065>,
			<6326 5693 5344 5129 5075 5066>,
			<6330 5717 5355 5130 5077 5068>,
			<6326 5732 5362 5130 5078 5070>,
			<6315 5738 5364 5129 5080 5072>,
			<6300 5740 5365 5129 5080 5073>,
			<6278 5732 5360 5128 5080 5073>,
			<6250 5718 5353 5127 5080 5073>,
			<6225 5707 5347 5126 5081 5073>,
			<6200 5696 5343 5126 5082 5074>,
			<6185 5686 5339 5126 5083 5074>,
			<6178 5673 5337 5127 5085 5076>,
			<6173 5664 5335 5129 5086 5077>,
			<6169 5670 5336 5131 5088 5079>,
			<6165 5691 5340 5133 5090 5080>,
			<6156 5699 5342 5136 5092 5082>,
			<6100 5664 5344 5141 5095 5084>,
			<6031 5619 5345 5147 5099 5086>,
			<6012 5601 5338 5155 5105 5091>,
			<6004 5590 5316 5164 5112 5097>,
			<5997 5579 5298 5163 5113 5099>,
			<5985 5564 5283 5145 5105 5093>,
			<5976 5551 5271 5126 5094 5085>,
			<5976 5539 5263 5115 5084 5077>,
			<5979 5528 5257 5107 5075 5068>,
			<5985 5526 5256 5106 5073 5066>,
			<6003 5530 5255 5106 5073 5066>,
			<6029 5538 5255 5107 5074 5066>,
			<6054 5553 5253 5109 5076 5068>,
			<6081 5577 5252 5113 5078 5070>,
			<6109 5604 5252 5115 5081 5073>,
			<6139 5633 5254 5117 5085 5076>,
			<6171 5666 5258 5119 5088 5080>,
			<6204 5703 5268 5121 5090 5082>,
			<6239 5743 5282 5123 5092 5085>,
			<6274 5787 5298 5122 5090 5083>,
			<6309 5836 5318 5121 5083 5075>,
			<6343 5888 5339 5121 5080 5072>,
			<6376 5945 5361 5121 5080 5072>,
			<6409 6005 5385 5122 5081 5074>,
			<6440 6067 5409 5125 5084 5077>,
			<6469 6131 5437 5131 5088 5083>,
			<6503 6198 5475 5132 5082 5075>,
			<6544 6267 5525 5133 5077 5068>,
			<6603 6322 5552 5131 5077 5069>,
			<6626 6352 5603 5145 5092 5087>,
			<6689 6415 5652 5156 5105 5101>,
			<6773 6482 5712 5169 5118 5114>,
			<6886 6557 5777 5184 5130 5123>,
			<7062 6644 5854 5195 5118 5108>,
			<7390 6774 5948 5179 5096 5087>,
			<8569 7036 6120 5182 5098 5089>,
			<12129 8125 6495 5208 5106 5094>,
			<23721 13666 7380 5257 5126 5113>,
			<23721 13666 7380 5257 5126 5113>,
			<23721 13666 7380 5257 5126 5113>;
	};

};
